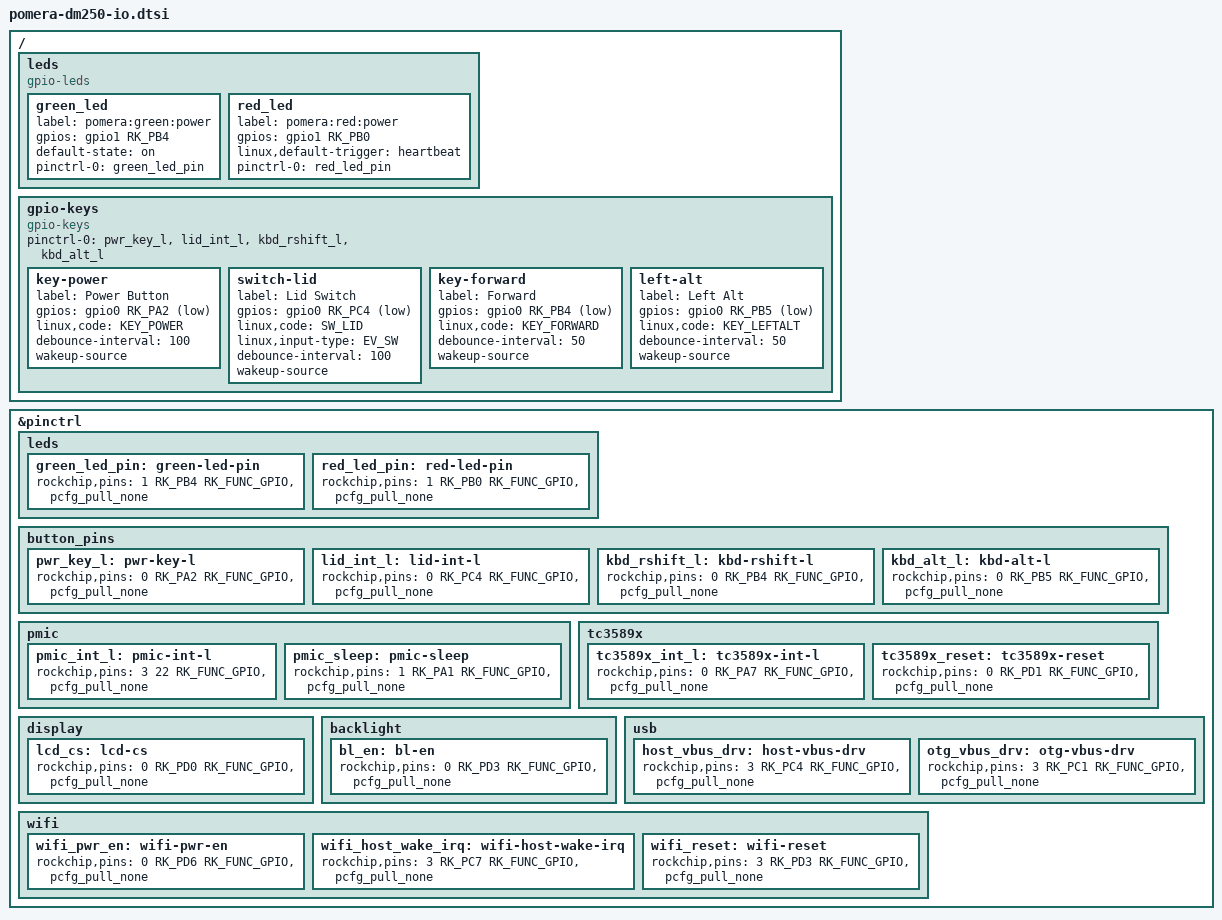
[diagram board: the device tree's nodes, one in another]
// SPDX-License-Identifier: (GPL-2.0+ OR MIT)
#include <dt-bindings/input/input.h>

/ {
        leds {
                compatible = "gpio-leds";
                status = "okay";
                
                green_led {
                        label = "pomera:green:power";
                        gpios = <&gpio1 RK_PB4 GPIO_ACTIVE_HIGH>;
                        default-state = "on";
                        pinctrl-names = "default";
                        pinctrl-0 = <&green_led_pin>;
                };
                
                red_led {
                        label = "pomera:red:power";
                        gpios = <&gpio1 RK_PB0 GPIO_ACTIVE_HIGH>;
                        /* default-state = "off"; */
			linux,default-trigger = "heartbeat";
                        pinctrl-names = "default";
                        pinctrl-0 = <&red_led_pin>;
                };
        };

	gpio-keys {
		compatible = "gpio-keys";
		pinctrl-names = "default";
		pinctrl-0 = <&pwr_key_l &lid_int_l &kbd_rshift_l &kbd_alt_l>;
		/* autorepeat; */
		status = "okay";

		key-power {
			label = "Power Button";
			gpios = <&gpio0 RK_PA2 GPIO_ACTIVE_LOW>;
			linux,code = <KEY_POWER>;
			debounce-interval = <100>;
			wakeup-source;
		};

		switch-lid {
                        label = "Lid Switch";
                        gpios = <&gpio0 RK_PC4 GPIO_ACTIVE_LOW>;
                        linux,code = <SW_LID>;
                        linux,input-type = <EV_SW>;
                        debounce-interval = <100>;
                        wakeup-source;
                };

		// Former Right Shift
                key-forward {
                        label = "Forward";
                        gpios = <&gpio0 RK_PB4 GPIO_ACTIVE_LOW>;
                        linux,code = <KEY_FORWARD>;
                        debounce-interval = <50>;
                        wakeup-source;
                };

                left-alt {
                        label = "Left Alt";
                        gpios = <&gpio0 RK_PB5 GPIO_ACTIVE_LOW>;
                        linux,code = <KEY_LEFTALT>;
                        debounce-interval = <50>;
                        wakeup-source;
                };
	};
};

&pinctrl {
        leds {
                green_led_pin: green-led-pin {
                        rockchip,pins = <1 RK_PB4 RK_FUNC_GPIO &pcfg_pull_none>;
                };

                red_led_pin: red-led-pin {
                        rockchip,pins = <1 RK_PB0 RK_FUNC_GPIO &pcfg_pull_none>;
                };
        };

	button_pins {
                pwr_key_l: pwr-key-l {
                        rockchip,pins = <0 RK_PA2 RK_FUNC_GPIO &pcfg_pull_none>;
                };
                
                lid_int_l: lid-int-l {
                        rockchip,pins = <0 RK_PC4 RK_FUNC_GPIO &pcfg_pull_none>;
                };

                kbd_rshift_l: kbd-rshift-l {
                        rockchip,pins = <0 RK_PB4 RK_FUNC_GPIO &pcfg_pull_none>;
                };

                kbd_alt_l: kbd-alt-l {
                        rockchip,pins = <0 RK_PB5 RK_FUNC_GPIO &pcfg_pull_none>;
                };
        };

	pmic {
		pmic_int_l: pmic-int-l {
                        rockchip,pins = <3 22 RK_FUNC_GPIO &pcfg_pull_none>;
			/* rockchip,pins = <1 RK_PB1 RK_FUNC_GPIO &pcfg_pull_none>; */
		};

		/* Pin for switching state between sleep and non-sleep state */
		pmic_sleep: pmic-sleep {
			rockchip,pins = <1 RK_PA1 RK_FUNC_GPIO &pcfg_pull_none>;
		};
        };

        tc3589x {
		tc3589x_int_l: tc3589x-int-l {
			rockchip,pins = <0 RK_PA7 RK_FUNC_GPIO &pcfg_pull_none>;
		};
                
		tc3589x_reset: tc3589x-reset {
			rockchip,pins = <0 RK_PD1 RK_FUNC_GPIO &pcfg_pull_none>;
		};
	};
        
	display {
		lcd_cs: lcd-cs {
			rockchip,pins = <0 RK_PD0 RK_FUNC_GPIO &pcfg_pull_none>;
		};
	};

        backlight {
		bl_en: bl-en {
			rockchip,pins = <0 RK_PD3 RK_FUNC_GPIO &pcfg_pull_none>;
		};
        };

	usb {
		host_vbus_drv: host-vbus-drv {
			rockchip,pins = <3 RK_PC4 RK_FUNC_GPIO &pcfg_pull_none>;
		};
                
		otg_vbus_drv: otg-vbus-drv {
			rockchip,pins = <3 RK_PC1 RK_FUNC_GPIO &pcfg_pull_none>;
		};
	};
        
	wifi {
		wifi_pwr_en: wifi-pwr-en {
			rockchip,pins = <0 RK_PD6 RK_FUNC_GPIO &pcfg_pull_none>;
		};

		wifi_host_wake_irq: wifi-host-wake-irq {
			rockchip,pins = <3 RK_PC7 RK_FUNC_GPIO &pcfg_pull_none>;
		};

		wifi_reset: wifi-reset {
			rockchip,pins = <3 RK_PD3 RK_FUNC_GPIO &pcfg_pull_none>;
		};
	};
};
